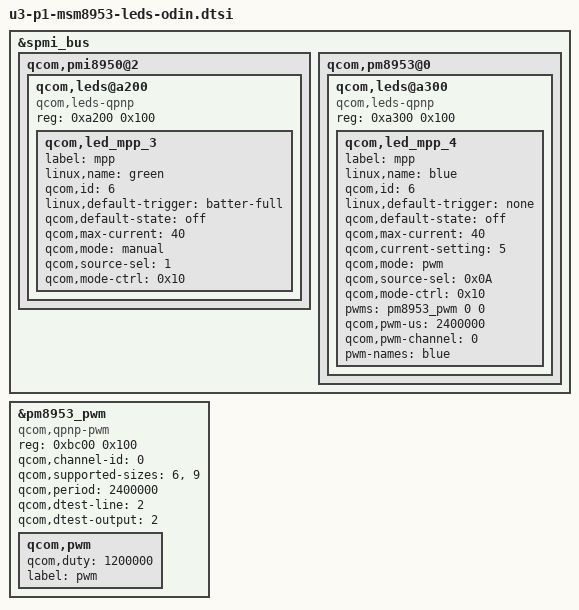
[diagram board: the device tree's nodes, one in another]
/* Copyright (c) 2014-2015, The Linux Foundation. All rights reserved.
 *
 * This program is free software; you can redistribute it and/or modify
 * it under the terms of the GNU General Public License version 2 and
 * only version 2 as published by the Free Software Foundation.
 *
 * This program is distributed in the hope that it will be useful,
 * but WITHOUT ANY WARRANTY; without even the implied warranty of
 * MERCHANTABILITY or FITNESS FOR A PARTICULAR PURPOSE.  See the
 * GNU General Public License for more details.
 */

&spmi_bus {
	qcom,pmi8950@2 {
		qcom,leds@a200 {
			compatible = "qcom,leds-qpnp";
			reg = <0xa200 0x100>;
			status = "okay";
			qcom,led_mpp_3 {
				label = "mpp";
				linux,name = "green";
				qcom,id = <6>;
				linux,default-trigger = "batter-full";
				qcom,default-state = "off";
				qcom,max-current = <40>;
				qcom,mode = "manual";
				qcom,source-sel = <1>;
				qcom,mode-ctrl = <0x10>;
			};
		};
	};
};

&spmi_bus {
	qcom,pm8953@0 {
		qcom,leds@a300 {
			compatible = "qcom,leds-qpnp";
			reg = <0xa300 0x100>;
			status = "okay";
			qcom,led_mpp_4 {
				label = "mpp";
				linux,name = "blue";
				qcom,id = <6>;
				linux,default-trigger = "none";
				qcom,default-state = "off";
				qcom,max-current = <40>;
				qcom,current-setting = <5>;
				qcom,mode = "pwm";
				qcom,source-sel = <0x0A>;
				qcom,mode-ctrl = <0x10>;
				pwms = <&pm8953_pwm 0 0>;
				qcom,pwm-us = <2400000>;
				qcom,pwm-channel = <0>;
				pwm-names = "blue";
			};
		};
	};
};


&pm8953_pwm {
	status = "okay";
	compatible = "qcom,qpnp-pwm";
	reg = <0xbc00 0x100>;
	reg-names = "qpnp-lpg-channel-base";
	qcom,channel-id = <0>;
	qcom,supported-sizes = <6>, <9>;
	qcom,period = <2400000>;
	#pwm-cells = <2>;
	qcom,dtest-line = <2>;
	qcom,dtest-output = <2>;
	qcom,pwm {
		qcom,duty = <1200000>;
		label = "pwm";
	};
};
